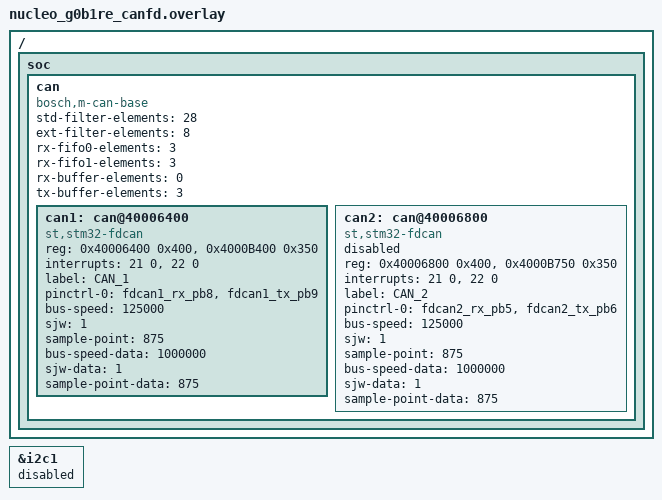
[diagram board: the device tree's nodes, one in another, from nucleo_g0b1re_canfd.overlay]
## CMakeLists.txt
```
cmake_minimum_required(VERSION 3.20.0)

set(DTC_OVERLAY_FILE nucleo_g0b1re_canfd.overlay)
set(BOARD nucleo_g0b1re)

find_package(Zephyr REQUIRED HINTS $ENV{ZEPHYR_BASE})
project(nucleo_g0b1re_canfd)

target_sources(app PRIVATE src/main.c)
```

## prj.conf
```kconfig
CONFIG_GPIO=y

CONFIG_CAN=y
CONFIG_CAN_FD_MODE=y

CONFIG_SPEED_OPTIMIZATIONS=y
```

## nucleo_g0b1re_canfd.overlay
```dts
/ {
	soc {
		can {
			compatible = "bosch,m-can-base";
			#address-cells = <1>;
			#size-cells = <1>;
			std-filter-elements = <28>;
			ext-filter-elements = <8>;
			rx-fifo0-elements = <3>;
			rx-fifo1-elements = <3>;
			rx-buffer-elements = <0>;
			tx-buffer-elements = <3>;

			can1: can@40006400 {
				compatible = "st,stm32-fdcan";
				#address-cells = <1>;
				#size-cells = <0>;
				reg = <0x40006400 0x400>, <0x4000B400 0x350>;
				reg-names = "m_can", "message_ram";
				interrupts = <21 0>, <22 0>;
				interrupt-names = "LINE_0", "LINE_1";
				status = "disabled";
				label = "CAN_1";
			};

			can2: can@40006800 {
				compatible = "st,stm32-fdcan";
				#address-cells = <1>;
				#size-cells = <0>;
				reg = <0x40006800 0x400>, <0x4000B750 0x350>;
				reg-names = "m_can", "message_ram";
				interrupts = <21 0>, <22 0>;
				interrupt-names = "LINE_0", "LINE_1";
				status = "disabled";
				label = "CAN_2";
			};
		};
	};	
};

&i2c1 {
	status = "disabled"; // PB8, PB9
};

&can1 {
	status = "okay";
	pinctrl-0 = <&fdcan1_rx_pb8 &fdcan1_tx_pb9>;
	pinctrl-names = "default";
	bus-speed = <125000>;
	sjw = <1>;
	sample-point = <875>;
	bus-speed-data = <1000000>;
	sjw-data = <1>;
	sample-point-data = <875>;
};

&can2 {
	// status = "okay"; // shared interrupt, can't enable both yet
	pinctrl-0 = <&fdcan2_rx_pb5 &fdcan2_tx_pb6>;
	pinctrl-names = "default";
	bus-speed = <125000>;
	sjw = <1>;
	sample-point = <875>;
	bus-speed-data = <1000000>;
	sjw-data = <1>;
	sample-point-data = <875>;
};
```

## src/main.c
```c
#include <zephyr.h>
#include <drivers/gpio.h>
#include <drivers/can.h>

const struct gpio_dt_spec led = GPIO_DT_SPEC_GET(DT_ALIAS(led0), gpios);

const struct device *can1 = DEVICE_DT_GET(DT_NODELABEL(can1));

const struct zcan_filter can_filter = {
	.id_type = CAN_STANDARD_IDENTIFIER,
	.rtr_mask = 0,
	.id_mask = 0
};

CAN_MSGQ_DEFINE(can_msgq, 16);

int main() {
	gpio_pin_configure_dt(&led, GPIO_OUTPUT_INACTIVE);

	can_set_mode(can1, CAN_LOOPBACK_MODE);
	can_set_bitrate(can1, 1000000, 8000000);
	can_add_rx_filter_msgq(can1, &can_msgq, &can_filter);

	struct zcan_frame txmsg = {
		.id = 0x69,
		.id_type = CAN_STANDARD_IDENTIFIER,
		.rtr = CAN_DATAFRAME,
		.dlc = 1,
		.fd = true,
		.brs = true
	};

	printk("Hello world!\r\n");
	while (1) {
		printk("hi %d\r\n", txmsg.data[0]++);
		can_send(can1, &txmsg, K_FOREVER, NULL, NULL);

		struct zcan_frame rxmsg;
		k_msgq_get(&can_msgq, &rxmsg, K_FOREVER);
		printk("bye %d\r\n", rxmsg.data[0]);

		gpio_pin_toggle_dt(&led);
		k_msleep(1000);
	}
}
```
